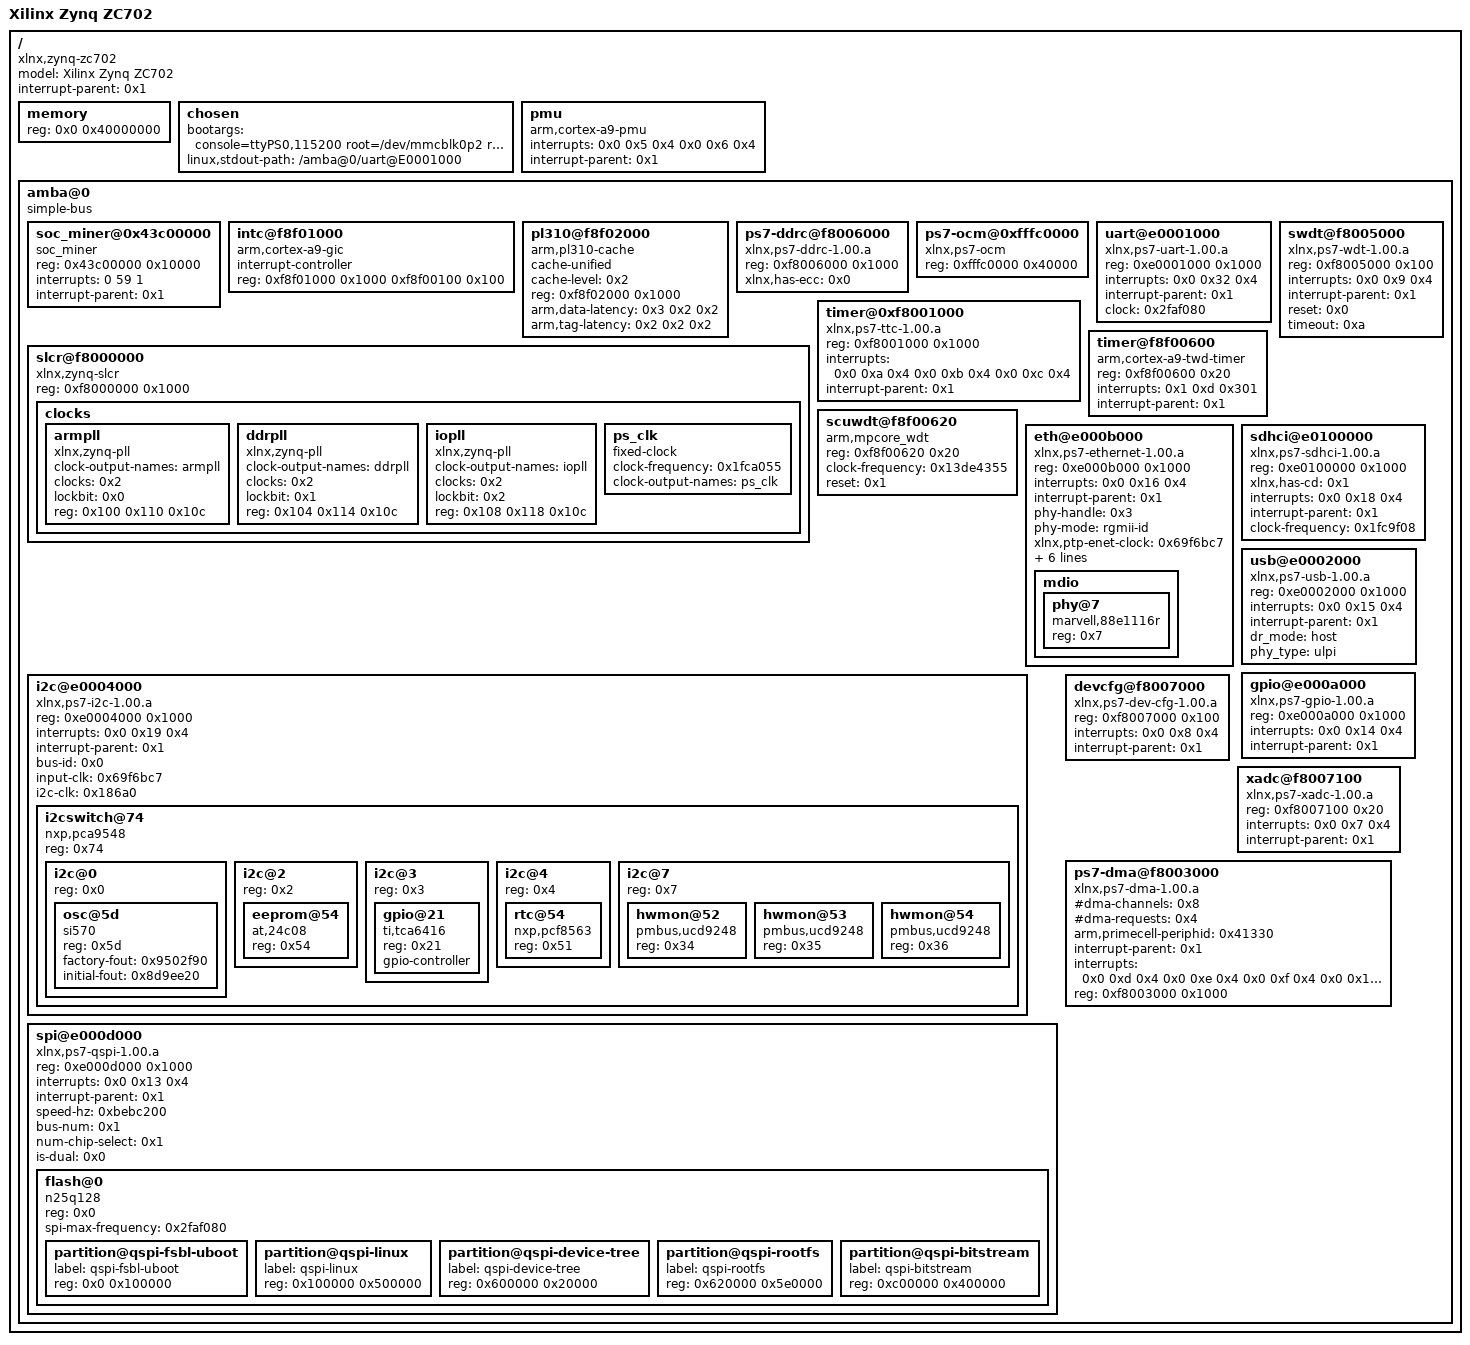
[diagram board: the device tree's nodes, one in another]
/dts-v1/;

/ {
	model = "Xilinx Zynq ZC702";
	compatible = "xlnx,zynq-zc702";
	#address-cells = <0x1>;
	#size-cells = <0x1>;
	interrupt-parent = <0x1>;

	memory {
		device_type = "memory";
		reg = <0x0 0x40000000>;
	};

	chosen {
		bootargs = "console=ttyPS0,115200 root=/dev/mmcblk0p2 rw earlyprintk";
		linux,stdout-path = "/amba@0/uart@E0001000";
	};

	pmu {
		compatible = "arm,cortex-a9-pmu";
		interrupts = <0x0 0x5 0x4 0x0 0x6 0x4>;
		interrupt-parent = <0x1>;
	};

	amba@0 {
		compatible = "simple-bus";
		#address-cells = <0x1>;
		#size-cells = <0x1>;
		ranges;

                soc_miner@0x43c00000 {
			compatible = "soc_miner";
			reg = <0x43c00000 0x10000>;
			interrupts = <0 59 1>;
			interrupt-parent = <0x1>;

                };
		intc@f8f01000 {
			interrupt-controller;
			compatible = "arm,cortex-a9-gic";
			#interrupt-cells = <0x3>;
			reg = <0xf8f01000 0x1000 0xf8f00100 0x100>;
			linux,phandle = <0x1>;
			phandle = <0x1>;
		};

		pl310@f8f02000 {
			compatible = "arm,pl310-cache";
			cache-unified;
			cache-level = <0x2>;
			reg = <0xf8f02000 0x1000>;
			arm,data-latency = <0x3 0x2 0x2>;
			arm,tag-latency = <0x2 0x2 0x2>;
		};

		ps7-ddrc@f8006000 {
			compatible = "xlnx,ps7-ddrc-1.00.a", "xlnx,ps7-ddrc";
			reg = <0xf8006000 0x1000>;
			xlnx,has-ecc = <0x0>;
		};

		ps7-ocm@0xfffc0000 {
			compatible = "xlnx,ps7-ocm";
			reg = <0xfffc0000 0x40000>;
		};

		uart@e0001000 {
			compatible = "xlnx,ps7-uart-1.00.a";
			reg = <0xe0001000 0x1000>;
			interrupts = <0x0 0x32 0x4>;
			interrupt-parent = <0x1>;
			clock = <0x2faf080>;
		};

		slcr@f8000000 {
			compatible = "xlnx,zynq-slcr";
			reg = <0xf8000000 0x1000>;

			clocks {
				#address-cells = <0x1>;
				#size-cells = <0x0>;

				armpll {
					#clock-cells = <0x0>;
					clock-output-names = "armpll";
					clocks = <0x2>;
					compatible = "xlnx,zynq-pll";
					lockbit = <0x0>;
					reg = <0x100 0x110 0x10c>;
				};

				ddrpll {
					#clock-cells = <0x0>;
					clock-output-names = "ddrpll";
					clocks = <0x2>;
					compatible = "xlnx,zynq-pll";
					lockbit = <0x1>;
					reg = <0x104 0x114 0x10c>;
				};

				iopll {
					#clock-cells = <0x0>;
					clock-output-names = "iopll";
					clocks = <0x2>;
					compatible = "xlnx,zynq-pll";
					lockbit = <0x2>;
					reg = <0x108 0x118 0x10c>;
				};

				ps_clk {
					#clock-cells = <0x0>;
					clock-frequency = <0x1fca055>;
					clock-output-names = "ps_clk";
					compatible = "fixed-clock";
					linux,phandle = <0x2>;
					phandle = <0x2>;
				};
			};
		};

		timer@0xf8001000 {
			compatible = "xlnx,ps7-ttc-1.00.a";
			reg = <0xf8001000 0x1000>;
			interrupts = <0x0 0xa 0x4 0x0 0xb 0x4 0x0 0xc 0x4>;
			interrupt-parent = <0x1>;
		};

		timer@f8f00600 {
			compatible = "arm,cortex-a9-twd-timer";
			reg = <0xf8f00600 0x20>;
			interrupts = <0x1 0xd 0x301>;
			interrupt-parent = <0x1>;
		};

		swdt@f8005000 {
			device_type = "watchdog";
			compatible = "xlnx,ps7-wdt-1.00.a";
			reg = <0xf8005000 0x100>;
			interrupts = <0x0 0x9 0x4>;
			interrupt-parent = <0x1>;
			reset = <0x0>;
			timeout = <0xa>;
		};

		scuwdt@f8f00620 {
			device_type = "watchdog";
			compatible = "arm,mpcore_wdt";
			reg = <0xf8f00620 0x20>;
			clock-frequency = <0x13de4355>;
			reset = <0x1>;
		};

		eth@e000b000 {
			compatible = "xlnx,ps7-ethernet-1.00.a";
			reg = <0xe000b000 0x1000>;
			interrupts = <0x0 0x16 0x4>;
			interrupt-parent = <0x1>;
			phy-handle = <0x3>;
			phy-mode = "rgmii-id";
			xlnx,ptp-enet-clock = <0x69f6bc7>;
			xlnx,slcr-div0-1000Mbps = <0x8>;
			xlnx,slcr-div0-100Mbps = <0x8>;
			xlnx,slcr-div0-10Mbps = <0x8>;
			xlnx,slcr-div1-1000Mbps = <0x1>;
			xlnx,slcr-div1-100Mbps = <0x5>;
			xlnx,slcr-div1-10Mbps = <0x32>;
			#address-cells = <0x1>;
			#size-cells = <0x0>;

			mdio {
				#address-cells = <0x1>;
				#size-cells = <0x0>;

				phy@7 {
					compatible = "marvell,88e1116r";
					device_type = "ethernet-phy";
					reg = <0x7>;
					linux,phandle = <0x3>;
					phandle = <0x3>;
				};
			};
		};

		i2c@e0004000 {
			compatible = "xlnx,ps7-i2c-1.00.a";
			reg = <0xe0004000 0x1000>;
			interrupts = <0x0 0x19 0x4>;
			interrupt-parent = <0x1>;
			bus-id = <0x0>;
			input-clk = <0x69f6bc7>;
			i2c-clk = <0x186a0>;
			#address-cells = <0x1>;
			#size-cells = <0x0>;

			i2cswitch@74 {
				compatible = "nxp,pca9548";
				#address-cells = <0x1>;
				#size-cells = <0x0>;
				reg = <0x74>;

				i2c@0 {
					#address-cells = <0x1>;
					#size-cells = <0x0>;
					reg = <0x0>;

					osc@5d {
						compatible = "si570";
						reg = <0x5d>;
						factory-fout = <0x9502f90>;
						initial-fout = <0x8d9ee20>;
					};
				};

				i2c@2 {
					#address-cells = <0x1>;
					#size-cells = <0x0>;
					reg = <0x2>;

					eeprom@54 {
						compatible = "at,24c08";
						reg = <0x54>;
					};
				};

				i2c@3 {
					#address-cells = <0x1>;
					#size-cells = <0x0>;
					reg = <0x3>;

					gpio@21 {
						compatible = "ti,tca6416";
						reg = <0x21>;
						gpio-controller;
						#gpio-cells = <0x2>;
					};
				};

				i2c@4 {
					#address-cells = <0x1>;
					#size-cells = <0x0>;
					reg = <0x4>;

					rtc@54 {
						compatible = "nxp,pcf8563";
						reg = <0x51>;
					};
				};

				i2c@7 {
					#address-cells = <0x1>;
					#size-cells = <0x0>;
					reg = <0x7>;

					hwmon@52 {
						compatible = "pmbus,ucd9248";
						reg = <0x34>;
					};

					hwmon@53 {
						compatible = "pmbus,ucd9248";
						reg = <0x35>;
					};

					hwmon@54 {
						compatible = "pmbus,ucd9248";
						reg = <0x36>;
					};
				};
			};
		};

		sdhci@e0100000 {
			compatible = "xlnx,ps7-sdhci-1.00.a";
			reg = <0xe0100000 0x1000>;
			xlnx,has-cd = <0x1>;
			interrupts = <0x0 0x18 0x4>;
			interrupt-parent = <0x1>;
			clock-frequency = <0x1fc9f08>;
		};

		usb@e0002000 {
			compatible = "xlnx,ps7-usb-1.00.a";
			reg = <0xe0002000 0x1000>;
			interrupts = <0x0 0x15 0x4>;
			interrupt-parent = <0x1>;
			dr_mode = "host";
			phy_type = "ulpi";
		};

		gpio@e000a000 {
			compatible = "xlnx,ps7-gpio-1.00.a";
			reg = <0xe000a000 0x1000>;
			interrupts = <0x0 0x14 0x4>;
			interrupt-parent = <0x1>;
		};

		spi@e000d000 {
			compatible = "xlnx,ps7-qspi-1.00.a";
			reg = <0xe000d000 0x1000>;
			interrupts = <0x0 0x13 0x4>;
			interrupt-parent = <0x1>;
			speed-hz = <0xbebc200>;
			bus-num = <0x1>;
			num-chip-select = <0x1>;
			#address-cells = <0x1>;
			#size-cells = <0x0>;
			is-dual = <0x0>;

			flash@0 {
				compatible = "n25q128";
				reg = <0x0>;
				spi-max-frequency = <0x2faf080>;
				#address-cells = <0x1>;
				#size-cells = <0x1>;

				partition@qspi-fsbl-uboot {
					label = "qspi-fsbl-uboot";
					reg = <0x0 0x100000>;
				};

				partition@qspi-linux {
					label = "qspi-linux";
					reg = <0x100000 0x500000>;
				};

				partition@qspi-device-tree {
					label = "qspi-device-tree";
					reg = <0x600000 0x20000>;
				};

				partition@qspi-rootfs {
					label = "qspi-rootfs";
					reg = <0x620000 0x5e0000>;
				};

				partition@qspi-bitstream {
					label = "qspi-bitstream";
					reg = <0xc00000 0x400000>;
				};
			};
		};

		devcfg@f8007000 {
			compatible = "xlnx,ps7-dev-cfg-1.00.a";
			reg = <0xf8007000 0x100>;
			interrupts = <0x0 0x8 0x4>;
			interrupt-parent = <0x1>;
		};

		xadc@f8007100 {
			compatible = "xlnx,ps7-xadc-1.00.a";
			reg = <0xf8007100 0x20>;
			interrupts = <0x0 0x7 0x4>;
			interrupt-parent = <0x1>;
		};

		ps7-dma@f8003000 {
			#dma-cells = <0x1>;
			#dma-channels = <0x8>;
			#dma-requests = <0x4>;
			arm,primecell-periphid = <0x41330>;
			compatible = "xlnx,ps7-dma-1.00.a", "arm,primecell", "arm,pl330";
			interrupt-parent = <0x1>;
			interrupts = <0x0 0xd 0x4 0x0 0xe 0x4 0x0 0xf 0x4 0x0 0x10 0x4 0x0 0x11 0x4 0x0 0x28 0x4 0x0 0x29 0x4 0x0 0x2a 0x4 0x0 0x2b 0x4>;
			reg = <0xf8003000 0x1000>;
		};
	};
};
